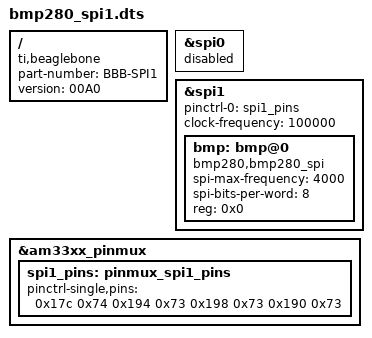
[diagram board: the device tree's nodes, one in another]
/dts-v1/;
/plugin/;

/{ /* this is our device tree overlay root node */

  compatible = "ti,beaglebone", "ti,beaglebone-black";
  part-number = "BBB-SPI1"; // you can choose any name here but it should be memorable
  version = "00A0";


  fragment@0 {
    target = <&spi0>;
    __overlay__ {
       status = "disabled";
    };
  };

  fragment@1 {
    target = <&spi1>;
    __overlay__ {
       status = "disabled";
    };
  };
 
 
  fragment@2 {
    target = <&am33xx_pinmux>; // this is a link to an already defined node in the device tree, so that node is overlayed with our modification

    __overlay__ {
      spi1_pins: pinmux_spi1_pins {
        pinctrl-single,pins = <
          0x17c 0x74  
          0x194 0x73 
          0x198 0x73
          0x190 0x73

        >;
      };
    };
  };

  fragment@3 {
    target = <&spi1>;

    __overlay__ {
      pinctrl-0 = <&spi1_pins>;
      #address-cells = <1>;
      #size-cells = <0>;

      clock-frequency = <100000>;
      status = "okay";

      bmp: bmp@0 { /* the real time clock defined as child of the i2c1 bus */
        compatible = "bmp280,bmp280_spi";
        spi-max-frequency = <4000>;
        spi-bits-per-word = <8>;
        reg = <0x0>;
        status = "okay";
      };
    };
  };
}; /* root node end */
